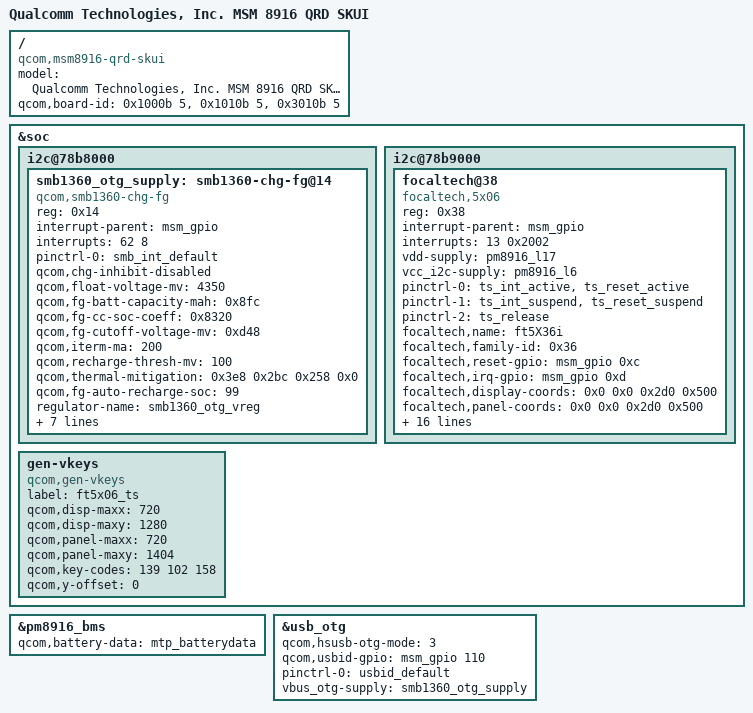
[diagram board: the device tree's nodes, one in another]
/* Copyright (c) 2014, The Linux Foundation. All rights reserved.
 *
 * This program is free software; you can redistribute it and/or modify
 * it under the terms of the GNU General Public License version 2 and
 * only version 2 as published by the Free Software Foundation.
 *
 * This program is distributed in the hope that it will be useful,
 * but WITHOUT ANY WARRANTY; without even the implied warranty of
 * MERCHANTABILITY or FITNESS FOR A PARTICULAR PURPOSE.  See the
 * GNU General Public License for more details.
 */

/dts-v1/;

#include "mlte5/msm8916-qrd-skui.dtsi"
#include "msm8916-memory.dtsi"

/ {
	model = "Qualcomm Technologies, Inc. MSM 8916 QRD SKUI";
	compatible = "qcom,msm8916-qrd-skui", "qcom,msm8916-qrd", "qcom,msm8916", "qcom,qrd";
	qcom,board-id = <0x1000b 5> , <0x1010b 5> , <0x3010b 5>;
};

&soc {
	i2c@78b8000 {
		smb1360_otg_supply: smb1360-chg-fg@14 {
			compatible = "qcom,smb1360-chg-fg";
			reg = <0x14>;
			interrupt-parent = <&msm_gpio>;
			interrupts = <62 8>;
			pinctrl-names = "default";
			pinctrl-0 = <&smb_int_default>;
			qcom,chg-inhibit-disabled;
			qcom,float-voltage-mv = <4350>;
			qcom,fg-batt-capacity-mah = <0x8fc>;
			qcom,fg-cc-soc-coeff = <0x8320>;
			qcom,fg-cutoff-voltage-mv = <0xd48>;
			qcom,iterm-ma = <200>;
			qcom,recharge-thresh-mv = <100>;
			qcom,thermal-mitigation = <0x3e8 0x2bc 0x258 0x0>;
			qcom,fg-auto-recharge-soc = <99>;
			regulator-name = "smb1360_otg_vreg";
			qcom,fg-delta-soc_reg = <0x1>;
			qcom,empty-soc-disabled;
			qcom,charging-led = <&msm_gpio 22 0>;
			qcom,otg-batt-curr-limit = <0x5dc>;
			qcom,fg-reset-at-pon;
			qcom,shdn-after-pwroff;
			qcom,thermistor-c1-coeff = <0x86da>;

		};
	};

	i2c@78b9000 { /* BLSP1 QUP5 */
		focaltech@38 {
			compatible = "focaltech,5x06";
			reg = <0x38>;
			interrupt-parent = <&msm_gpio>;
			interrupts = <13 0x2002>;
			vdd-supply = <&pm8916_l17>;
			vcc_i2c-supply = <&pm8916_l6>;
			/* pins used by touchscreen */
			pinctrl-names = "pmx_ts_active","pmx_ts_suspend","pmx_ts_release";
			pinctrl-0 = <&ts_int_active &ts_reset_active>;
			pinctrl-1 = <&ts_int_suspend &ts_reset_suspend>;
			pinctrl-2 = <&ts_release>;
				focaltech,name = "ft5X36i";
			focaltech,family-id = <0x36>;
			focaltech,reset-gpio = <&msm_gpio 0xc 0x0>;
			focaltech,irq-gpio = <&msm_gpio 0xd 0x2002>;
			focaltech,display-coords = <0x0 0x0 0x2d0 0x500>;
			focaltech,panel-coords = <0x0 0x0 0x2d0 0x500>;
			focaltech,virtual_key;
			focaltech,button-map= <139 102 158>;
			focaltech,no-force-update;
			focaltech,i2c-pull-up;
			focaltech,group-id = <1>;
			focaltech,hard-reset-delay-ms = <20>;
			focaltech,soft-reset-delay-ms = <200>;
			focaltech,num-max-touches = <5>;
			focaltech,fw-delay-aa-ms = <30>;
			focaltech,fw-delay-55-ms = <30>;
			focaltech,fw-upgrade-id1 = <0x79>;
			focaltech,fw-upgrade-id2 = <0x18>;
			focaltech,fw-delay-readid-ms = <10>;
			focaltech,fw-delay-era-flsh-ms = <2000>;
			focaltech,ignore-id-check;
			focaltech,keep-pwr-suppend;
		};
	};

	gen-vkeys {
		compatible = "qcom,gen-vkeys";
		label = "ft5x06_ts";
		qcom,disp-maxx = <720>;
		qcom,disp-maxy = <1280>;
		qcom,panel-maxx = <720>;
		qcom,panel-maxy = <1404>;
		qcom,key-codes = <139 102 158>;
		qcom,y-offset = <0>;
	};
};


&pm8916_bms {
	status = "ok";
	qcom,battery-data = <&mtp_batterydata>;
};

&usb_otg {
	qcom,hsusb-otg-mode = <3>;
	qcom,usbid-gpio = <&msm_gpio 110 0>;
	pinctrl-names = "default";
	pinctrl-0 = <&usbid_default>;
	vbus_otg-supply = <&smb1360_otg_supply>;
};
